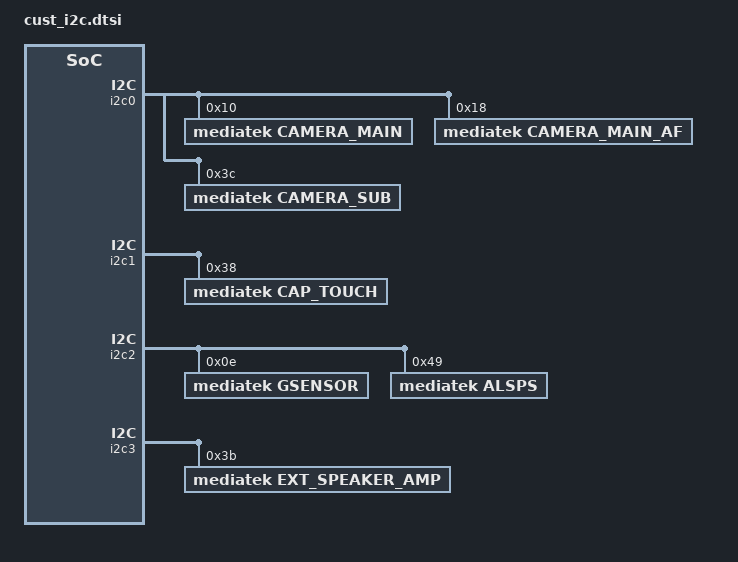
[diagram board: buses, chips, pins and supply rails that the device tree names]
/*
 * Generated by MTK SP DrvGen Version 03.13.6 for MT6735M. Copyright MediaTek Inc. (C) 2013.
 * Wed Jan 18 00:45:51 2017
 * Do Not Modify the File.
 */

/*************************
 * I2C DTSI File
*************************/

&i2c0 {
	CAMERA_MAIN@10 {
		compatible = "mediatek,CAMERA_MAIN";
		reg = <0x10>;
	};

	CAMERA_MAIN_AF@18 {
		compatible = "mediatek,CAMERA_MAIN_AF";
		reg = <0x18>;
	};

	CAMERA_SUB@3C {
		compatible = "mediatek,CAMERA_SUB";
		reg = <0x3C>;
	};

};

&i2c1 {
	CAP_TOUCH@38 {
		compatible = "mediatek,CAP_TOUCH";
		reg = <0x38>;
	};

};

&i2c2 {
	GSENSOR@0E {
		compatible = "mediatek,GSENSOR";
		reg = <0x0E>;
	};

	ALSPS@49 {
		compatible = "mediatek,ALSPS";
		reg = <0x49>;
	};

};

&i2c3 {
	EXT_SPEAKER_AMP@3B {
		compatible = "mediatek,EXT_SPEAKER_AMP";
		reg = <0x3B>;
	};

};

